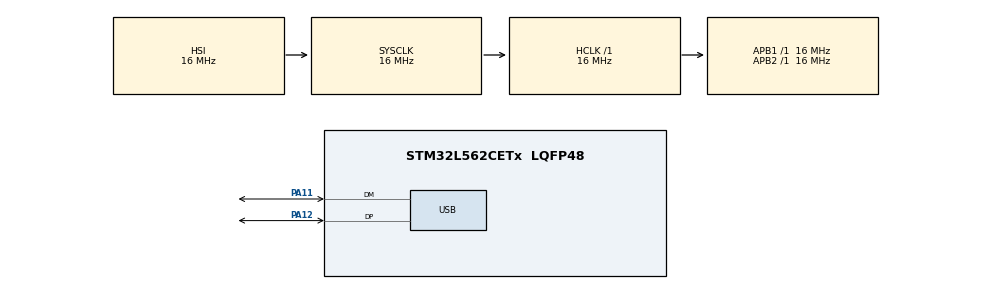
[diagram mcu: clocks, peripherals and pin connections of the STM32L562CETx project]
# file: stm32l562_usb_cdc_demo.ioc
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Mcu.Family=STM32L5
Mcu.Name=STM32L562CETx
Mcu.Package=LQFP48
NVIC.PriorityGroup=NVIC_PRIORITYGROUP_3
NVIC.USB_FS_IRQn=true\:0\:0\:false\:false\:true\:false\:true
PA11.Mode=Device
PA11.Signal=USB_DM
PA12.Mode=Device
PA12.Signal=USB_DP
ProjectManager.HeapSize=0x200
ProjectManager.StackSize=0x400
ProjectManager.TargetToolchain=STM32CubeIDE
RCC.ADCFreq_Value=48000000
RCC.AHBFreq_Value=16000000
RCC.APB1Freq_Value=16000000
RCC.APB1TimFreq_Value=16000000
RCC.APB2Freq_Value=16000000
RCC.APB2TimFreq_Value=16000000
RCC.CK48CLockSelection=RCC_USBCLKSOURCE_HSI48
RCC.CortexFreq_Value=16000000
RCC.HCLKFreq_Value=16000000
RCC.HSE_VALUE=16000000
RCC.HSI48_VALUE=48000000
RCC.HSI_VALUE=16000000
RCC.LSE_VALUE=32768
RCC.MSI_VALUE=4000000
RCC.PLLN=16
RCC.PLLSAI1N=24
RCC.SYSCLKFreq_VALUE=16000000
RCC.SYSCLKSource=RCC_SYSCLKSOURCE_HSI
RCC.USBFreq_Value=48000000
RCC.VCOOutputFreq_Value=64000000
USB_DEVICE.CLASS_NAME_FS=CDC
USB_DEVICE.USBD_LPM_ENABLED=0
USB_DEVICE.VirtualMode=Cdc
USB_DEVICE.VirtualModeFS=Cdc_FS
VP_PWR_VS_DBSignals.Mode=DisableDeadBatterySignals
VP_PWR_VS_SECSignals.Mode=Security/Privilege
VP_USB_DEVICE_VS_USB_DEVICE_CDC_FS.Mode=CDC_FS
board=custom

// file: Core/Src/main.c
/* USER CODE BEGIN Header */
/**
  ******************************************************************************
  * @file           : main.c
  * @brief          : Main program body
  ******************************************************************************
  * @attention
  *
  * <h2><center>&copy; Copyright (c) 2021 STMicroelectronics.
  * All rights reserved.</center></h2>
  *
  * This software component is licensed by ST under BSD 3-Clause license,
  * the "License"; You may not use this file except in compliance with the
  * License. You may obtain a copy of the License at:
  *                        opensource.org/licenses/BSD-3-Clause
  *
  ******************************************************************************
  */
/* USER CODE END Header */
#include "main.h"
#include "usb_device.h"

/* USER CODE BEGIN Includes */
#include "usbd_cdc_if.h"
/* USER CODE END Includes */

void SystemClock_Config(void);
static void MX_GPIO_Init(void);

int main(void)
{

  /* MCU Configuration--------------------------------------------------------*/

  /* Reset of all peripherals, Initializes the Flash interface and the Systick. */
  HAL_Init();

  /* Configure the system clock */
  SystemClock_Config();

  /* Initialize all configured peripherals */
  MX_GPIO_Init();
  MX_USB_Device_Init();

  /* Infinite loop */
  /* USER CODE BEGIN WHILE */
  uint8_t tx_buffer[] = "Hello, World!\r\n";
  while (1)
  {
	CDC_Transmit_FS(tx_buffer, sizeof(tx_buffer));
	HAL_Delay(1000);
    /* USER CODE END WHILE */

  }
}

void SystemClock_Config(void)
{
  RCC_OscInitTypeDef RCC_OscInitStruct = {0};
  RCC_ClkInitTypeDef RCC_ClkInitStruct = {0};

  /** Configure the main internal regulator output voltage
  */
  if (HAL_PWREx_ControlVoltageScaling(PWR_REGULATOR_VOLTAGE_SCALE2) != HAL_OK)
  {
    Error_Handler();
  }
  /** Initializes the RCC Oscillators according to the specified parameters
  * in the RCC_OscInitTypeDef structure.
  */
  RCC_OscInitStruct.OscillatorType = RCC_OSCILLATORTYPE_HSI48|RCC_OSCILLATORTYPE_HSI;
  RCC_OscInitStruct.HSIState = RCC_HSI_ON;
  RCC_OscInitStruct.HSI48State = RCC_HSI48_ON;
  RCC_OscInitStruct.HSICalibrationValue = RCC_HSICALIBRATION_DEFAULT;
  RCC_OscInitStruct.PLL.PLLState = RCC_PLL_NONE;
  if (HAL_RCC_OscConfig(&RCC_OscInitStruct) != HAL_OK)
  {
    Error_Handler();
  }
  /** Initializes the CPU, AHB and APB buses clocks
  */
  RCC_ClkInitStruct.ClockType = RCC_CLOCKTYPE_HCLK|RCC_CLOCKTYPE_SYSCLK
                              |RCC_CLOCKTYPE_PCLK1|RCC_CLOCKTYPE_PCLK2;
  RCC_ClkInitStruct.SYSCLKSource = RCC_SYSCLKSOURCE_HSI;
  RCC_ClkInitStruct.AHBCLKDivider = RCC_SYSCLK_DIV1;
  RCC_ClkInitStruct.APB1CLKDivider = RCC_HCLK_DIV1;
  RCC_ClkInitStruct.APB2CLKDivider = RCC_HCLK_DIV1;

  if (HAL_RCC_ClockConfig(&RCC_ClkInitStruct, FLASH_LATENCY_1) != HAL_OK)
  {
    Error_Handler();
  }
}

static void MX_GPIO_Init(void)
{

  /* GPIO Ports Clock Enable */
  __HAL_RCC_GPIOA_CLK_ENABLE();

}

void Error_Handler(void)
{
  __disable_irq();
  while (1)
  {
  }
}

/************************ (C) COPYRIGHT STMicroelectronics *****END OF FILE****/
